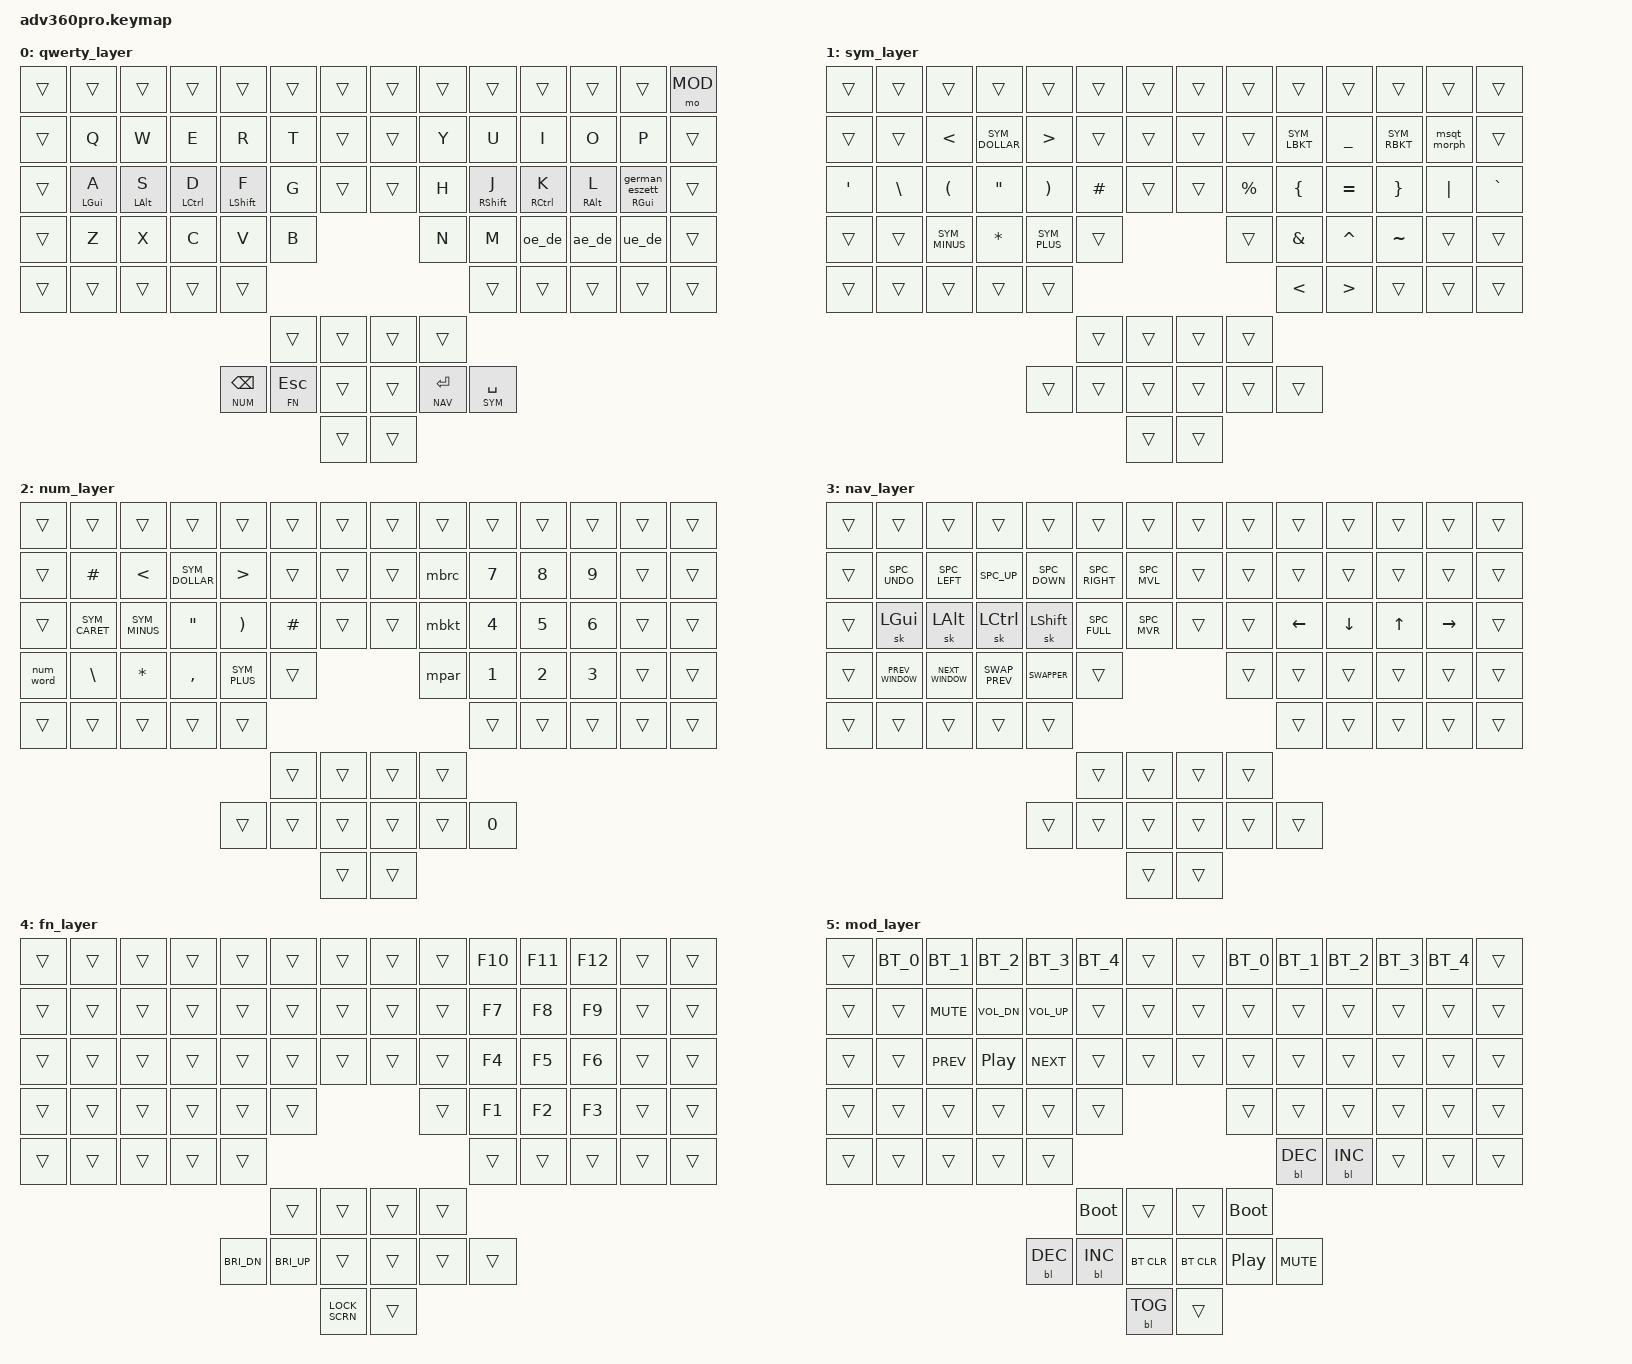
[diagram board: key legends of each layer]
#include <behaviors.dtsi> 
#include <dt-bindings/zmk/keys.h>
#include <dt-bindings/zmk/bt.h>
#include <dt-bindings/zmk/outputs.h>
#include <dt-bindings/zmk/rgb.h>
#include <dt-bindings/zmk/backlight.h>

#include "adv360pro_keypos.h"
#include "zmk_helper.h"

#define ___ &trans


/* */
/* Layer references  */
#define QWERTY 0
#define SYM 1
#define NUM 2
#define NAV 3
#define FN 4
#define MOD 5

/* Global settings */
#include "general.h"

/* Home row mods */
#include "homerow_mods.h"

/* Macros and shortcuts */
#include "custom_behaviors.h"

/* combos */

#undef COMBO_HOOK
#define COMBO_HOOK global-quick-tap-ms = <100>;

    
/ { /*start of device tree */

    behaviors {
    unicode_input: unicode_input {
        compatible = "zmk,behavior-macro";
        #binding-cells = <0>;
        bindings = <&macro_press &kp LCTRL>, <&macro_press &kp LSHFT>, <&macro_tap &kp U>, <&macro_release &kp LSHFT>, <&macro_release &kp LCTRL>;
        label = "UNICODE_INPUT";
        };

    hm_ss: homerow_mod_ss {
            compatible = "zmk,behavior-hold-tap";
            #binding-cells = <2>;
            tapping-term-ms = <200>;
            quick-tap-ms = <125>;
            flavor = "tap-preferred";
            bindings = <&kp>, <&german_eszett>;
            label = "HOMEROW_MOD_SS";
    };

    };




macros {
         ae_de: ae_macro {
            compatible = "zmk,behavior-macro";
            #binding-cells = <0>;
            wait-ms = <0>; // Added wait time
            tap-ms = <1>;  // Added tap time
            bindings = <&kp A &kp E>;
            label = "AE_MACRO"; // Added label
            };



       german_eszett: german_eszett {
            compatible = "zmk,behavior-macro";
            #binding-cells = <0>;
            wait-ms = <1>; // Added wait time
            tap-ms = <1>;  // Added tap time
            bindings = <&macro_press &kp LALT>, <&macro_tap &kp S>, <&macro_release &kp LALT>;
            label = "GERMAN_ESZETT";
             };
        


        oe_de: oe_macro {
            compatible = "zmk,behavior-macro";
            #binding-cells = <0>;
            wait-ms = <1>; // Added wait time
            tap-ms = <1>;  // Added tap time
            bindings = <&kp O &kp E>;
            label = "OE_MACRO"; // Added label
            };


        ue_de: ue_macro {
            compatible = "zmk,behavior-macro";
            #binding-cells = <0>;
            wait-ms = <1>; // Added wait time
            tap-ms = <1>;  // Added tap time
            bindings = <&kp U &kp E>;
            label = "UE_MACRO"; // Added label
            };
        };

   combos {
        compatible = "zmk,combos";
        
        combo_esc {
            timeout-ms = <20>;
            key-positions = <LT3 LT2>;
            bindings = <&kp ESC>;
            layers = <0 1 2>;
        };
        combo_space {
            timeout-ms = <20>;
            key-positions = <RM1 RM2>;
            bindings = <&kp SPACE>;
            layers = <0 1 2>;
        };
        combo_ret {
            timeout-ms = <20>;
            key-positions = <RM0 RM1>;
            bindings = <&kp RETURN>;
            layers = <0 1 2>;
        };
         combo_tab {
            timeout-ms = <20>;
            key-positions = <RT2 RT3>;
            bindings = <&kp TAB>;
            layers = <0 1 2>;
        };
        combo_shift_tab {
            timeout-ms = <50>;
            key-positions = <RT1 RT2>; 
            bindings = <&kp LS(TAB)>;
            layers = <0 1 2>;
        };
        combo_bspc {
            timeout-ms = <20>;
            key-positions = <LM1 LM0>;
            bindings = <&kp BSPC>;
            layers = <0 1 2>;
        };
         



        combo_cut {
            timeout-ms = <20>;
            key-positions = <LB4 LB3>;
            bindings = <&kp LG(X)>;
            layers = <0 1 2>;
        };
        combo_copy {
            timeout-ms = <20>;
            key-positions = <LB3 LB2>;
            bindings = <&kp LG(C)>;
            layers = <0 1 2>;
        };
        combo_paste {
            timeout-ms = <20>;
            key-positions = <LB2 LB1>;
            bindings = <&kp LG(V)>;
            layers = <0 1 2>;
        };
       combo_undo {
            timeout-ms = <20>;
            key-positions = <LB4 LB1>;
            bindings = <&kp LG(Z)>;
            layers = <0 1 2>;
        };



        combo_qmark {
            timeout-ms = <20>;
            key-positions = <RB2 RB3>;
            bindings = <&kp QMARK>;
            layers = <0 1 2>;
        };
        combo_excl {
            timeout-ms = <20>;
            key-positions = <RB1 RB4>;
            bindings = <&kp EXCL>;
            layers = <0 1 2>;
        };
        combo_dot {
            timeout-ms = <20>;
            key-positions = <RB1 RB2>;
            bindings = <&kp DOT>;
            layers = <0 1 2>;
        };
        combo_colon {
            timeout-ms = <20>;
            key-positions = <RB1 RB3>;
            bindings = <&kp COLON>;
            layers = <0 1 2>;
        };
        combo_comma {
            timeout-ms = <20>;
            key-positions = <RB3 RB4>;
            bindings = <&kp COMMA>;
            layers = <0 1 2>;
        };
        combo_semi {
            timeout-ms = <20>;
            key-positions = <RB2 RB4>;
            bindings = <&kp SEMI>;
            layers = <0 1 2>;
        };
};





    chosen {
        zmk,matrix_transform = &urobs_transform;
           }; /* remove unused keys from layout and move thumb cluster to bottom */







    keymap {
        compatible = "zmk,keymap";
 
        qwerty_layer {
            bindings = <
     ___            ___           ___           ___           ___           ___            ___              ___            ___           ___           ___           ___             ___                  &mo MOD
     ___            &kp Q         &kp W         &kp E         &kp R         &kp T          ___              ___            &kp Y         &kp U         &kp I         &kp O          &kp P                  ___
     ___            &hml LGUI A  &hml LALT S   &hml LCTRL D   &hml LSHFT F  &kp G          ___              ___            &kp H         &hmr RSHFT J  &hmr RCTRL K  &hmr RALT L    &hm_ss RGUI 0          ___
     ___            &kp Z         &kp X         &kp C         &kp V         &kp B                                          &kp N         &kp M         &oe_de        &ae_de &ue_de                 ___
     ___            ___           ___           ___           ___                                                                        ___           ___           ___             ___                   ___
                                                                             ___           ___              ___            ___    
                                                              &lt NUM BSPC  &lt FN ESC     ___              ___            &lt NAV RET  &lt SYM SPC
                                                                                           ___              ___
                    >;
                    };



        
        sym_layer {
          bindings = <
     ___            ___           ___           ___           ___           ___            ___              ___            ___           ___            ___          ___           ___            ___
     ___            ___           &kp LT        SYM_DOLLAR    &kp GT        ___            ___              ___            ___           SYM_LBKT      &kp UNDER     SYM_RBKT       &msqt_morph   ___
     &kp SQT        &kp BSLH      &kp LPAR      &kp DQT       &kp RPAR      &kp HASH       ___              ___            &kp PRCNT     &kp LBRC      &kp EQUAL     &kp RBRC       &kp PIPE      &kp GRAVE
     ___            ___           SYM_MINUS     &kp STAR      SYM_PLUS      ___                                            ___           &kp AMPS      &kp CARET     &kp TILDE      ___           ___
     ___            ___           ___           ___           ___                                                                        &kp LT        &kp GT        ___           ___            ___
                                                                             ___           ___              ___           ___
                                                               ___           ___           ___              ___           ___            ___
                                                                                           ___              ___
            >;
        };

        num_layer {
            bindings = <
     ___            ___           ___           ___           ___           ___             ___              ___            ___          ___           ___           ___           ___            ___
     ___            &kp HASH      &kp LT         SYM_DOLLAR   &kp GT        ___             ___              ___            &mbrc        &kp N7        &kp N8        &kp N9        ___            ___
     ___            SYM_CARET     SYM_MINUS      &kp DQT      &kp RPAR      &kp HASH        ___              ___            &mbkt        &kp N4        &kp N5        &kp N6        ___            ___
     &num_word      &kp BSLH      &kp STAR      &kp COMMA      SYM_PLUS       ___                                           &mpar        &kp N1        &kp N2        &kp N3        ___            ___
     ___            ___           ___           ___           ___                                                                        ___           ___           ___           ___            ___
                                                                             ___           ___              ___           ___
                                                               ___           ___           ___              ___           ___           &kp N0
                                                                                           ___              ___
                    >;
                    };


       


        

        nav_layer {
            bindings = <
     ___            ___           ___           ___           ___           ___            ___              ___            ___           ___           ___           ___           ___            ___
     ___            SPC_UNDO      SPC_LEFT      SPC_UP        SPC_DOWN      SPC_RIGHT      SPC_MVL          ___            ___           ___           ___           ___           ___            ___
     ___            &sk LGUI      &sk LALT      &sk LCTRL     &sk LSHFT     SPC_FULL       SPC_MVR          ___            ___           &kp LEFT      &kp DOWN      &kp UP        &kp RIGHT      ___
     ___            PREV_WINDOW   NEXT_WINDOW   SWAP_PREV     SWAPPER       ___                                            ___           ___           ___           ___           ___            ___
     ___            ___           ___           ___           ___                                                                        ___           ___           ___           ___            ___
                                                                             ___           ___              ___           ___
                                                               ___           ___           ___              ___           ___           ___
                                                                                           ___              ___
            >;
        };

         fn_layer {
            bindings = <
     ___            ___           ___           ___            ___          ___            ___              ___            ___           &kp F10       &kp F11       &kp F12       ___            ___
     ___            ___           ___           ___           ___           ___            ___              ___            ___           &kp F7        &kp F8        &kp F9        ___            ___
     ___            ___           ___           ___           ___           ___            ___              ___            ___           &kp F4        &kp F5        &kp F6        ___            ___
     ___            ___           ___           ___           ___           ___                                            ___           &kp F1        &kp F2        &kp F3        ___            ___
     ___            ___           ___           ___           ___                                                                        ___           ___           ___           ___            ___
                                                                             ___           ___              ___           ___
                                                               &kp C_BRI_DN  &kp C_BRI_UP  ___              ___           ___           ___
                                                                                           LOCK_SCRN        ___
            >;
        };

        mod_layer {
            bindings = <

     ___            BT_0          BT_1          BT_2          BT_3          BT_4           ___              ___            BT_0          BT_1          BT_2          BT_3          BT_4           ___
     ___            ___           &kp C_MUTE    &kp C_VOL_DN  &kp C_VOL_UP  ___            ___              ___            ___           ___           ___           ___           ___            ___
     ___            ___           &kp C_PREV    &kp C_PP      &kp C_NEXT    ___            ___              ___            ___           ___           ___           ___           ___            ___
     ___            ___           ___           ___           ___           ___                                            ___           ___           ___           ___           ___            ___
     ___            ___           ___           ___           ___                                                                        &bl BL_DEC    &bl BL_INC    ___           ___            ___
                                                                             &bootloader   ___              ___           &bootloader
                                                               &bl BL_DEC    &bl BL_INC    &bt BT_CLR       &bt BT_CLR    &kp C_PP      &kp C_MUTE
                                                                                           &bl BL_TOG      ___
            >;
        };


    };
};
